# RA register map
Vendor: Renesas; Series: All Chips; File version: x.xx
Registers are 32-bit, read-write, reset 0x0 unless marked. A register's access mark holds for its fields unless they carry their own. Offsets are from the block's base; [hi:lo] are bit positions; lines under a group give offsets from that group; {n}, {i} and the like mark numbered series.

## R_DOC — Data Operation Circuit
Base 0x40054100
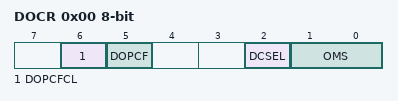
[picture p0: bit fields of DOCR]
0x00 DOCR 8-bit — DOC Control Register
  [6] DOPCFCL — DOPCF Clear
    0=Maintains the DOPCF flag state; 1=Clears the DOPCF flag
  [5] DOPCF ro — Data Operation Circuit Flag
  [2] DCSEL — Detection Condition Select
    0=DOPCF is set when data mismatch is detected; 1=DOPCF is set when data match is detected
  [1:0] OMS — Operating Mode Select
    0=Data comparison mode; 1=Data addition mode; 2=Data subtraction mode; 3=Setting prohibited
0x02 DODIR 16-bit — DOC Data Input Register
  [15:0] DODIR — 16-bit read-write register in which 16-bit data for use in the operations are stored.
0x04 DODSR 16-bit — DOC Data Setting Register
  [15:0] DODSR — This register stores 16-bit data for use as a reference in data comparison mode. This register also stores the results of operations in data addition and data subtraction modes.

## R_DTC — Data Transfer Controller
Base 0x40005400
0x00 DTCCR 8-bit reset 0x8 — DTC Control Register
  [4] RRS — DTC Transfer Information Read Skip Enable.
    0=Do not skip transfer information read; 1=Skip transfer information read when vector numbers match
0x04 DTCVBR — DTC Vector Base Register
  [31:0] DTCVBR — DTC Vector Base Address.Note: A value cannot be set in the lower-order 10 bits. These bits are fixed to 0.
0x0C DTCST 8-bit — DTC Module Start Register
  [0] DTCST — DTC Module Start
    0=DTC module stop; 1=DTC module start
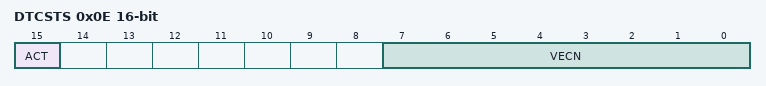
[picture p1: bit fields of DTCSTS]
0x0E DTCSTS 16-bit ro — DTC Status Register
  [15] ACT — DTC Active Flag
    0=DTC transfer operation is not in progress; 1=DTC transfer operation is in progress
  [7:0] VECN — DTC-Activating Vector Number MonitoringThese bits indicate the vector number for the activating source when DTC transfer is in progress.The value is only valid if DTC transfer is in progress (the value of the ACT flag is 1)

## R_ELC — Event Link Controller
Base 0x40041000
0x00 ELCR 8-bit — Event Link Controller Register
  [7] ELCON — All Event Link Enable
    0=ELC function is disabled; 1=ELC function is enabled
{0x2+2i} ELSEGR[{i}] (i=0..1) group — Event Link Software Event Generation Register
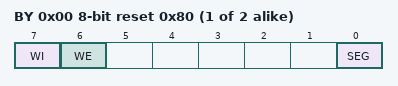
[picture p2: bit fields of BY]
  0x00 BY 8-bit reset 0x80 — Event Link Software Event Generation Register
    [7] WI wo — ELSEGR Register Write Disable
      0=Write to ELSEGR register is enabled; 1=Write to ELSEGR register is disabled
    [6] WE — SEG Bit Write Enable
      0=Write to SEG bit is disabled; 1=Write to SEG bit is enabled
    [0] SEG wo — Software Event Generation
      0=Normal operation; 1=Software event is generated
{0x10+4i} ELSR[{i}] (i=0..22) group — Event Link Setting Register {i}
  0x00 HA 16-bit — Event Link Setting Register
    [8:0] ELS — Event Link Select
      0=Event output to the corresponding peripheral module is disabled; other=others (Set the number for the event signal to be linked.)

## R_ETHERC_EPTPC_CFG — Ethernet PTP Configuration
Base 0x40064500
0x00 PTRSTR — EPTPC Reset Register
  [0] RESET — EPTPC Software Reset
    0=Do not reset the EPTPC; 1=Reset the EPTPC. Do not access the EPTPC-related registers other than this register while a software reset is being issued.
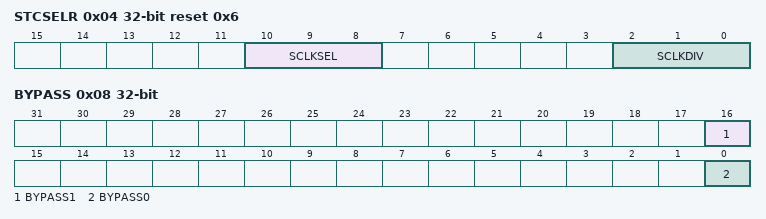
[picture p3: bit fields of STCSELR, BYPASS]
0x04 STCSELR reset 0x6 — STCA Clock Select Register
  [10:8] SCLKSEL — STCA Clock Select
    0=PCLKA clock divided by 1 to 6; 2=Input clock from the REF50CK0 pin; 3=Input clock from the REF50CK1 pin; other=others (Settings other than above are prohibited.)
  [2:0] SCLKDIV — PCLKA Clock Frequency Division
    1=1; {v}=1/{v} (v=2..6); other=others (Settings other than above are prohibited.)
0x08 BYPASS — Bypass 1588 module Register
  [16] BYPASS1 — Bypass 1588 module for Ether 1ch
    0=to use 1588 module for Ether 1ch; 1=to bypass 1588 module for Ether 1ch
  [0] BYPASS0 — Bypass 1588 module for Ether 0ch
    0=to use 1588 module for Ether 0ch; 1=to bypass 1588 module for Ether 0ch
